AUTOSAR XML (schema 00046)
package /ComponentTypes
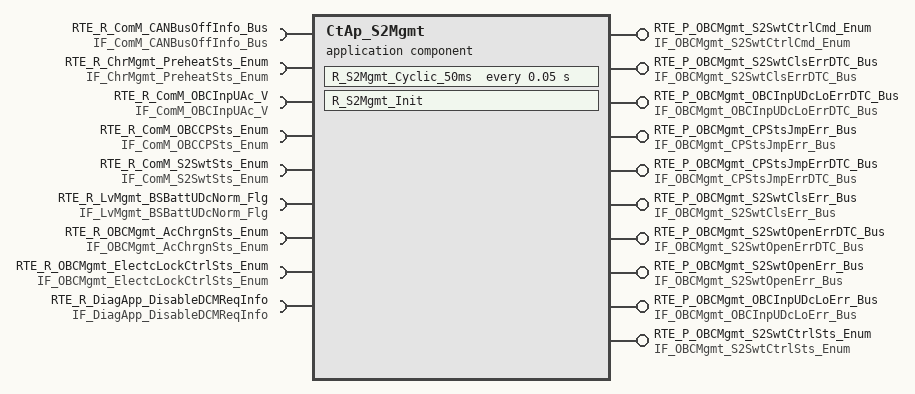
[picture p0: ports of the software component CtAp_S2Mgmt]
  application sw component type CtAp_S2Mgmt
    require port RTE_R_ComM_CANBusOffInfo_Bus: required-interface=IF_ComM_CANBusOffInfo_Bus
      required-com-specs:
        data-element=tec_ComM_EPTCANBusOffInfo_Bus, filter=data-filter-type=ALWAYS, init-value=fields=[ComM_MonStatEPTCANBusOffInfo:0, ComM_MonResEPTCANBusOffInfo:0, ComM_ErrStatEPTCANBusOffInfo:0, ComM_ErrResEPTCANBusOffInfo:0]
        data-element=tec_ComM_CHCANBusOffInfo_Bus, filter=data-filter-type=ALWAYS, init-value=fields=[ComM_MonStatCHCANBusOffInfo:0, ComM_MonResCHCANBusOffInfo:0, ComM_ErrStatCHCANBusOffInfo:0, ComM_ErrResCHCANBusOffInfo:0]
        data-element=tec_ComM_EPTCANBusOffDTCInfo_Bus, filter=data-filter-type=ALWAYS, init-value=fields=[ComM_MonStatEPTCANBusOffDTCInfo:0, ComM_MonResEPTCANBusOffDTCInfo:0, ComM_ErrStatEPTCANBusOffDTCInfo:0, ComM_ErrResEPTCANBusOffDTCInfo:0]
        data-element=tec_ComM_CHCANBusOffDTCInfo_Bus, filter=data-filter-type=ALWAYS, init-value=fields=[ComM_MonStatCHCANBusOffDTCInfo:0, ComM_MonResCHCANBusOffDTCInfo:0, ComM_ErrStatCHCANBusOffDTCInfo:0, ComM_ErrResCHCANBusOffDTCInfo:0]
        data-element=tec_ComM_DCCANBusOffDTCInfo_Bus, init-value=fields=[ComM_MonStatDCCANDTCBusOffInfo:0, ComM_MonResDCCANDTCBusOffInfo:0, ComM_ErrStatDCCANDTCBusOffInfo:0, ComM_ErrResDCCANDTCBusOffInfo:0]
        data-element=tec_ComM_DCCANBusOffInfo_Bus, init-value=fields=[ComM_MonStatDCCANBusOffInfo:0, ComM_MonResDCCANBusOffInfo:0, ComM_ErrStatDCCANBusOffInfo:0, ComM_ErrResDCCANBusOffInfo:0]
    provide port RTE_P_OBCMgmt_S2SwtCtrlCmd_Enum: nonqueued-sender-com-spec{data-element=tec_OBCMgmt_S2SwtCtrlCmd_Enum, init-value=0}, provided-interface=IF_OBCMgmt_S2SwtCtrlCmd_Enum
    provide port RTE_P_OBCMgmt_S2SwtClsErrDTC_Bus: nonqueued-sender-com-spec{data-element=tec_OBCMgmt_S2SwtClsErrDTC_Bus, init-value=fields=[OBCMgmt_MonStatS2SwtClsErrDTC:0, OBCMgmt_MonResS2SwtClsErrDTC:0, OBCMgmt_ErrStatS2SwtClsErrDTC:0, OBCMgmt_ErrResS2SwtClsErrDTC:0]}, provided-interface=IF_OBCMgmt_S2SwtClsErrDTC_Bus
    provide port RTE_P_OBCMgmt_OBCInpUDcLoErrDTC_Bus: nonqueued-sender-com-spec{data-element=tec_OBCMgmt_OBCInpUDcLoErrDTC_Bus, init-value=fields=[OBCMgmt_MonStatOBCInpUDcLoErrDTC:0, OBCMgmt_MonResOBCInpUDcLoErrDTC:0, OBCMgmt_ErrStatOBCInpUDcLoErrDTC:0, OBCMgmt_ErrResOBCInpUDcLoErrDTC:0]}, provided-interface=IF_OBCMgmt_OBCInpUDcLoErrDTC_Bus
    require port RTE_R_ChrMgmt_PreheatSts_Enum: nonqueued-receiver-com-spec{data-element=tec_ChrMgmt_PreheatSts_Enum, filter=data-filter-type=ALWAYS, init-value=0}, required-interface=IF_ChrMgmt_PreheatSts_Enum
    provide port RTE_P_OBCMgmt_CPStsJmpErr_Bus: nonqueued-sender-com-spec{data-element=tec_OBCMgmt_CPStsJmpErr_Bus, init-value=fields=[OBCMgmt_MonStatCPStsJmpErr:0, OBCMgmt_MonResCPStsJmpErr:0, OBCMgmt_ErrStatCPStsJmpErr:0, OBCMgmt_ErrResCPStsJmpErr:0]}, provided-interface=IF_OBCMgmt_CPStsJmpErr_Bus
    provide port RTE_P_OBCMgmt_CPStsJmpErrDTC_Bus: nonqueued-sender-com-spec{data-element=tec_OBCMgmt_CPStsJmpErrDTC_Bus, init-value=fields=[OBCMgmt_MonStatCPStsJmpErrDTC:0, OBCMgmt_MonResCPStsJmpErrDTC:0, OBCMgmt_ErrStatCPStsJmpErrDTC:0, OBCMgmt_ErrResCPStsJmpErrDTC:0]}, provided-interface=IF_OBCMgmt_CPStsJmpErrDTC_Bus
    require port RTE_R_ComM_OBCInpUAc_V: nonqueued-receiver-com-spec{data-element=tec_ComM_OBCInpUAc_V, filter=data-filter-type=ALWAYS, init-value=0}, required-interface=IF_ComM_OBCInpUAc_V
    4 x provide port:
      RTE_P_OBCMgmt_S2SwtClsErr_Bus: nonqueued-sender-com-spec{data-element=tec_OBCMgmt_S2SwtClsErr_Bus, init-value=fields=[OBCMgmt_MonStatS2SwtClsErr:0, OBCMgmt_MonResS2SwtClsErr:0, OBCMgmt_ErrStatS2SwtClsErr:0, OBCMgmt_ErrResS2SwtClsErr:0]}, provided-interface=IF_OBCMgmt_S2SwtClsErr_Bus
      RTE_P_OBCMgmt_S2SwtOpenErrDTC_Bus: nonqueued-sender-com-spec{data-element=tec_OBCMgmt_S2SwtOpenErrDTC_Bus, init-value=fields=[OBCMgmt_MonStatS2SwtOpenErrDTC:0, OBCMgmt_MonResS2SwtOpenErrDTC:0, OBCMgmt_ErrStatS2SwtOpenErrDTC:0, OBCMgmt_ErrResS2SwtOpenErrDTC:0]}, provided-interface=IF_OBCMgmt_S2SwtOpenErrDTC_Bus
      RTE_P_OBCMgmt_S2SwtOpenErr_Bus: nonqueued-sender-com-spec{data-element=tec_OBCMgmt_S2SwtOpenErr_Bus, init-value=fields=[OBCMgmt_MonStatS2SwtOpenErr:0, OBCMgmt_MonResS2SwtOpenErr:0, OBCMgmt_ErrStatS2SwtOpenErr:0, OBCMgmt_ErrResS2SwtOpenErr:0]}, provided-interface=IF_OBCMgmt_S2SwtOpenErr_Bus
      RTE_P_OBCMgmt_OBCInpUDcLoErr_Bus: nonqueued-sender-com-spec{data-element=tec_OBCMgmt_OBCInpUDcLoErr_Bus, init-value=fields=[OBCMgmt_MonStatOBCInpUDcLoErr:0, OBCMgmt_MonResOBCInpUDcLoErr:0, OBCMgmt_ErrStatOBCInpUDcLoErr:0, OBCMgmt_ErrResOBCInpUDcLoErr:0]}, provided-interface=IF_OBCMgmt_OBCInpUDcLoErr_Bus
    require port RTE_R_ComM_OBCCPSts_Enum: nonqueued-receiver-com-spec{data-element=tec_ComM_OBCCPSts_Enum, filter=data-filter-type=ALWAYS, init-value=0}, required-interface=IF_ComM_OBCCPSts_Enum
    require port RTE_R_ComM_S2SwtSts_Enum: nonqueued-receiver-com-spec{data-element=tec_ComM_S2SwtSts_Enum, filter=data-filter-type=ALWAYS, init-value=0}, required-interface=IF_ComM_S2SwtSts_Enum
    provide port RTE_P_OBCMgmt_S2SwtCtrlSts_Enum: nonqueued-sender-com-spec{data-element=tec_OBCMgmt_S2SwtCtrlSts_Enum, init-value=0}, provided-interface=IF_OBCMgmt_S2SwtCtrlSts_Enum
    4 x require port:
      RTE_R_LvMgmt_BSBattUDcNorm_Flg: nonqueued-receiver-com-spec{data-element=tec_LvMgmt_BSBattUDcNorm_Flg, filter=data-filter-type=ALWAYS, init-value=0}, required-interface=IF_LvMgmt_BSBattUDcNorm_Flg
      RTE_R_OBCMgmt_AcChrgnSts_Enum: nonqueued-receiver-com-spec{data-element=tec_OBCMgmt_AcChrgnSts_Enum, filter=data-filter-type=ALWAYS, init-value=0}, required-interface=IF_OBCMgmt_AcChrgnSts_Enum
      RTE_R_OBCMgmt_ElectcLockCtrlSts_Enum: nonqueued-receiver-com-spec{data-element=tec_OBCMgmt_ElectcLockCtrlSts_Enum, filter=data-filter-type=ALWAYS, init-value=0}, required-interface=IF_OBCMgmt_ElectcLockCtrlSts_Enum
      RTE_R_DiagApp_DisableDCMReqInfo: nonqueued-receiver-com-spec{data-element=tec_DiagApp_DisableDCMReqInfo, filter=data-filter-type=ALWAYS, init-value=0}, required-interface=IF_DiagApp_DisableDCMReqInfo
    behavior CtAp_S2Mgmt_InternalBehavior
      timing event TMT_R_S2Mgmt_Cyclic_50ms: start-on-event=R_S2Mgmt_Cyclic_50ms, period=0.05
      init event CtAp_S2Mgmt_InitEvent: start-on-event=R_S2Mgmt_Init
      runnable R_S2Mgmt_Cyclic_50ms
        data-receive-point-by-arguments:
          9 x access:
            REC_RTE_R_ChrMgmt_PreheatSts_Enum_tec_ChrMgmt_PreheatSts_Enum: accessed-variable=RTE_R_ChrMgmt_PreheatSts_Enum.tec_ChrMgmt_PreheatSts_Enum
            REC_RTE_R_ComM_CANBusOffInfo_Bus_tec_ComM_EPTCANBusOffInfo_Bus: accessed-variable=RTE_R_ComM_CANBusOffInfo_Bus.tec_ComM_EPTCANBusOffInfo_Bus
            REC_RTE_R_ComM_OBCCPSts_Enum_tec_ComM_OBCCPSts_Enum: accessed-variable=RTE_R_ComM_OBCCPSts_Enum.tec_ComM_OBCCPSts_Enum
            REC_RTE_R_ComM_OBCInpUAc_V_tec_ComM_OBCInpUAc_V: accessed-variable=RTE_R_ComM_OBCInpUAc_V.tec_ComM_OBCInpUAc_V
            REC_RTE_R_ComM_S2SwtSts_Enum_tec_ComM_S2SwtSts_Enum: accessed-variable=RTE_R_ComM_S2SwtSts_Enum.tec_ComM_S2SwtSts_Enum
            REC_RTE_R_LvMgmt_BSBattUDcNorm_Flg_tec_LvMgmt_BSBattUDcNorm_Flg: accessed-variable=RTE_R_LvMgmt_BSBattUDcNorm_Flg.tec_LvMgmt_BSBattUDcNorm_Flg
            REC_RTE_R_OBCMgmt_AcChrgnSts_Enum_tec_OBCMgmt_AcChrgnSts_Enum: accessed-variable=RTE_R_OBCMgmt_AcChrgnSts_Enum.tec_OBCMgmt_AcChrgnSts_Enum
            REC_RTE_R_OBCMgmt_ElectcLockCtrlSts_Enum_tec_OBCMgmt_ElectcLockCtrlSts_Enum: accessed-variable=RTE_R_OBCMgmt_ElectcLockCtrlSts_Enum.tec_OBCMgmt_ElectcLockCtrlSts_Enum
            REC_RTE_R_DiagApp_DisableDCMReqInfo_tec_DiagApp_DisableDCMReqInfo: accessed-variable=RTE_R_DiagApp_DisableDCMReqInfo.tec_DiagApp_DisableDCMReqInfo
        data-send-points:
          10 x access:
            SEND_RTE_P_OBCMgmt_CPStsJmpErrDTC_Bus_tec_OBCMgmt_CPStsJmpErrDTC_Bus: accessed-variable=RTE_P_OBCMgmt_CPStsJmpErrDTC_Bus.tec_OBCMgmt_CPStsJmpErrDTC_Bus
            SEND_RTE_P_OBCMgmt_CPStsJmpErr_Bus_tec_OBCMgmt_CPStsJmpErr_Bus: accessed-variable=RTE_P_OBCMgmt_CPStsJmpErr_Bus.tec_OBCMgmt_CPStsJmpErr_Bus
            SEND_RTE_P_OBCMgmt_OBCInpUDcLoErrDTC_Bus_tec_OBCMgmt_OBCInpUDcLoErrDTC_Bus: accessed-variable=RTE_P_OBCMgmt_OBCInpUDcLoErrDTC_Bus.tec_OBCMgmt_OBCInpUDcLoErrDTC_Bus
            SEND_RTE_P_OBCMgmt_OBCInpUDcLoErr_Bus_tec_OBCMgmt_OBCInpUDcLoErr_Bus: accessed-variable=RTE_P_OBCMgmt_OBCInpUDcLoErr_Bus.tec_OBCMgmt_OBCInpUDcLoErr_Bus
            SEND_RTE_P_OBCMgmt_S2SwtClsErrDTC_Bus_tec_OBCMgmt_S2SwtClsErrDTC_Bus: accessed-variable=RTE_P_OBCMgmt_S2SwtClsErrDTC_Bus.tec_OBCMgmt_S2SwtClsErrDTC_Bus
            SEND_RTE_P_OBCMgmt_S2SwtClsErr_Bus_tec_OBCMgmt_S2SwtClsErr_Bus: accessed-variable=RTE_P_OBCMgmt_S2SwtClsErr_Bus.tec_OBCMgmt_S2SwtClsErr_Bus
            SEND_RTE_P_OBCMgmt_S2SwtCtrlCmd_Enum_tec_OBCMgmt_S2SwtCtrlCmd_Enum: accessed-variable=RTE_P_OBCMgmt_S2SwtCtrlCmd_Enum.tec_OBCMgmt_S2SwtCtrlCmd_Enum
            SEND_RTE_P_OBCMgmt_S2SwtOpenErrDTC_Bus_tec_OBCMgmt_S2SwtOpenErrDTC_Bus: accessed-variable=RTE_P_OBCMgmt_S2SwtOpenErrDTC_Bus.tec_OBCMgmt_S2SwtOpenErrDTC_Bus
            SEND_RTE_P_OBCMgmt_S2SwtOpenErr_Bus_tec_OBCMgmt_S2SwtOpenErr_Bus: accessed-variable=RTE_P_OBCMgmt_S2SwtOpenErr_Bus.tec_OBCMgmt_S2SwtOpenErr_Bus
            SEND_RTE_P_OBCMgmt_S2SwtCtrlSts_Enum_tec_OBCMgmt_S2SwtCtrlSts_Enum: accessed-variable=RTE_P_OBCMgmt_S2SwtCtrlSts_Enum.tec_OBCMgmt_S2SwtCtrlSts_Enum
      runnable R_S2Mgmt_Init
  swc implementation CtAp_S2Mgmt_Implementation: behavior=CtAp_S2Mgmt_InternalBehavior
